# LPC5506 register map
Vendor: nxp.com; File version: 1.0
CPU: CM33 r2p0, little endian, MPU, FPU, VTOR, 3 interrupt priority bits
Registers are 32-bit, read-write, reset 0x0 unless marked. A register's access mark holds for its fields unless they carry their own. Offsets are from the block's base; [hi:lo] are bit positions; lines under a group give offsets from that group; {n}, {i} and the like mark numbered series.

## RNG
Base 0x4003A000
0x00 RANDOM_NUMBER ro — This register contains a random 32 bit number which is computed on demand, at each time it is read
  [31:0] RANDOM_NUMBER — This register contains a random 32 bit number which is computed on demand, at each time it is read.
0x04 ENCRYPTED_NUMBER — This register contains a random 32 bit number which is pre-computed
  [31:0] ENCRYPTED_NUMBER — This register contains a random 32 bit number which is pre-computed.
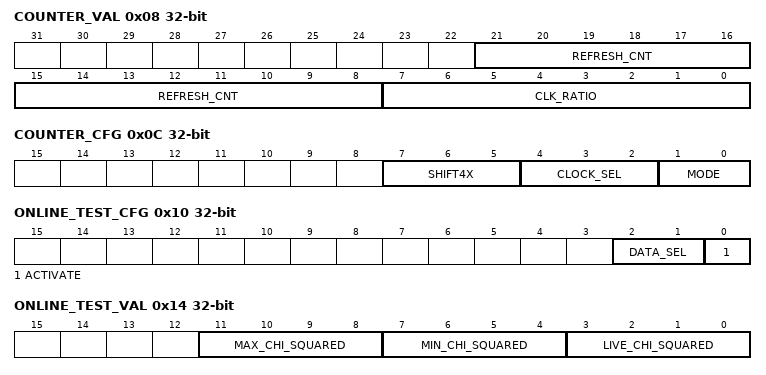
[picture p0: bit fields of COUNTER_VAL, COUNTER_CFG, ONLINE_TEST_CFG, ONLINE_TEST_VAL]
0x08 COUNTER_VAL (reset mask 0x1FFF)
  [21:8] REFRESH_CNT ro — Incremented (till max possible value) each time COUNTER was updated since last reading to any *_NUMBER.
  [7:0] CLK_RATIO ro — Gives the ratio between the internal clocks frequencies and the register clock frequency for evaluation and certification purposes.
0x0C COUNTER_CFG
  [7:5] SHIFT4X — To be used to add precision to clock_ratio and determine 'entropy refill'.
  [4:2] CLOCK_SEL — Selects the internal clock on which to compute statistics.
  [1:0] MODE — 00: disabled 01: update once.
0x10 ONLINE_TEST_CFG
  [2:1] DATA_SEL — Selects source on which to apply online test: 00: LSB of COUNTER: raw data from one or all sources of entropy 01: MSB of COUNTER: raw data from one or all sources of entropy 10: RANDOM_NUMBER 11: ENCRYPTED_NUMBER 'activate' should be set to 'disabled' before changing this field.
  [0] ACTIVATE — 0: disabled 1: activated Update rythm for VAL depends on COUNTER_CFG if data_sel is set to COUNTER.
0x14 ONLINE_TEST_VAL
  [11:8] MAX_CHI_SQUARED ro — This field is reset when 'activate'==0.
  [7:4] MIN_CHI_SQUARED ro — This field is reset when 'activate'==0.
  [3:0] LIVE_CHI_SQUARED ro — This value is updated as described in field 'activate'.
0x18 ENTROPY_INJECT (reset mask 0x3)
  [31:0] ENTROPY — Use this register to inject or restore entropy 32 bits at a time. Writing is blocking thus see to it to have analog clocks activated. Injection can be usefull to add contribution from an external source of entropy, like for example LSBs of an ADC or of a temperature sensor. Restore can be usefull to store N random numbers in central memory before going powerdown then restore this entropy to RNG IP after power-up. It is useless to inject or restore more than 1*(number of RNGs) 32b words consecutively. Recommendation is to inject 1*(number of RNGs) words, and possibly later (2*32 clock cycles of slowest analog clock) inject again 1*(number of RNGs) words. Then maximum capacity of restoration is reached: about 44 bits per RNG (not to be mistaken with maximum capacity of entropy accumulation which is about 100 bits per RNG). You can inject less than 32 bits words (let unused bits to 0). Injection cannot degrade overall performance due to the fact that some internal PRNGs are excluded on purpose from this external action.
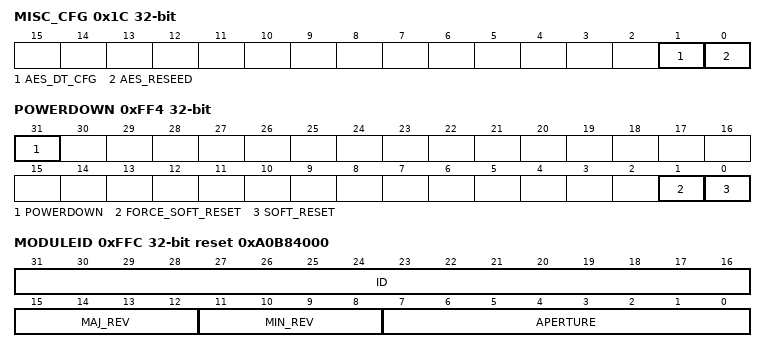
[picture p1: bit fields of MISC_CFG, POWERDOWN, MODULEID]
0x1C MISC_CFG
  [1] AES_DT_CFG — Set this bit to re-seed AES.
  [0] AES_RESEED — If set, ENCRYPTED_NUMBER generation becomes predictable, provided all secrets and current internal state are known: independant from entropy source.
0xFF4 POWERDOWN — Powerdown mode (standard but certainly useless here)
  [31] POWERDOWN — When set all accesses to standard registers are blocked.
  [1] FORCE_SOFT_RESET — When used with softreset it forces CORE_RESETN to low on acknowledge from CORE.
  [0] SOFT_RESET — Request softreset that will go low automaticaly after acknowledge from CORE.
0xFFC MODULEID ro reset 0xA0B84000 — IP identifier
  [31:16] ID — Identifier.
  [15:12] MAJ_REV — Major revision i.
  [11:8] MIN_REV — Minor revision i.
  [7:0] APERTURE — Aperture i.

## PLU — LPC80X Programmable Logic Unit (PLU)
Base 0x4003D000
{0x0+0x20*i} LUT[{i}] (i=0..25) group
  {0x0+4j} LUT_INP_MUX{j} (j=0..4) — LUTn input x MUX
    [5:0] LUTn_INPx — Selects the input source to be connected to LUT0 input0. For each LUT, the slot associated with the output from LUTn itself is tied low.
      {v}=plu_inputs{v} (The PLU primary inputs {v}.) (v=0..5); {v}=lut_outputs{v-6} (The output of LUT{v-6}.) (v=6..31); {v}=state{v-32} (v=32..35)
{0x800+4i} LUT_TRUTH[{i}] (i=0..25) — Specifies the Truth Table contents for LUTLUTn
  [31:0] LUTn_TRUTH — Specifies the Truth Table contents for LUT0..
0x900 OUTPUTS — Provides the current state of the 8 designated PLU Outputs.
  [7:0] OUTPUT_STATE ro — Provides the current state of the 8 designated PLU Outputs..
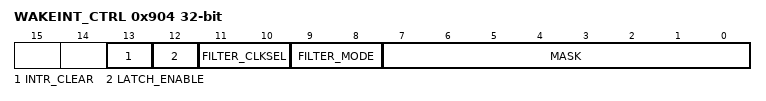
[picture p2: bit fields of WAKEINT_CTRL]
0x904 WAKEINT_CTRL — Wakeup interrupt control for PLU
  [13] INTR_CLEAR write-1-clears — Write to clear wakeint_latched
  [12] LATCH_ENABLE — latch the interrupt , then can be cleared with next bit INTR_CLEAR
  [11:10] FILTER_CLKSEL — hclk is divided by 2**filter_clksel.
    0=FRO1MHZ (Selects the 1 MHz low-power oscillator as the filter clock.); 1=FRO12MHZ (Selects the 12 Mhz FRO as the filter clock.); 2=OTHER_CLOCK (Selects a third filter clock source, if provided.)
  [9:8] FILTER_MODE — control input of the PLU, add filtering for glitch.
    0=BYPASS (Bypass mode.); 1=FILTER1CLK (Filter 1 clock period.); 2=FILTER2CLK (Filter 2 clock period.); 3=FILTER3CLK (Filter 3 clock period.)
  [7:0] MASK — Interrupt mask (which of the 8 PLU Outputs contribute to interrupt)
{0xC00+4i} OUTPUT_MUX[{i}] (i=0..7) — Selects the source to be connected to PLU Output OUTPUT_n
  [4:0] OUTPUTn — Selects the source to be connected to PLU Output 0.
    {v}=plu_output{v} (The PLU output {v}.) (v=0..25); {v}=state{v-26} (v=26..29)

## Notices in the file
Copyright 2016-2020 NXP
All rights reserved.
SPDX-License-Identifier: BSD-3-Clause
